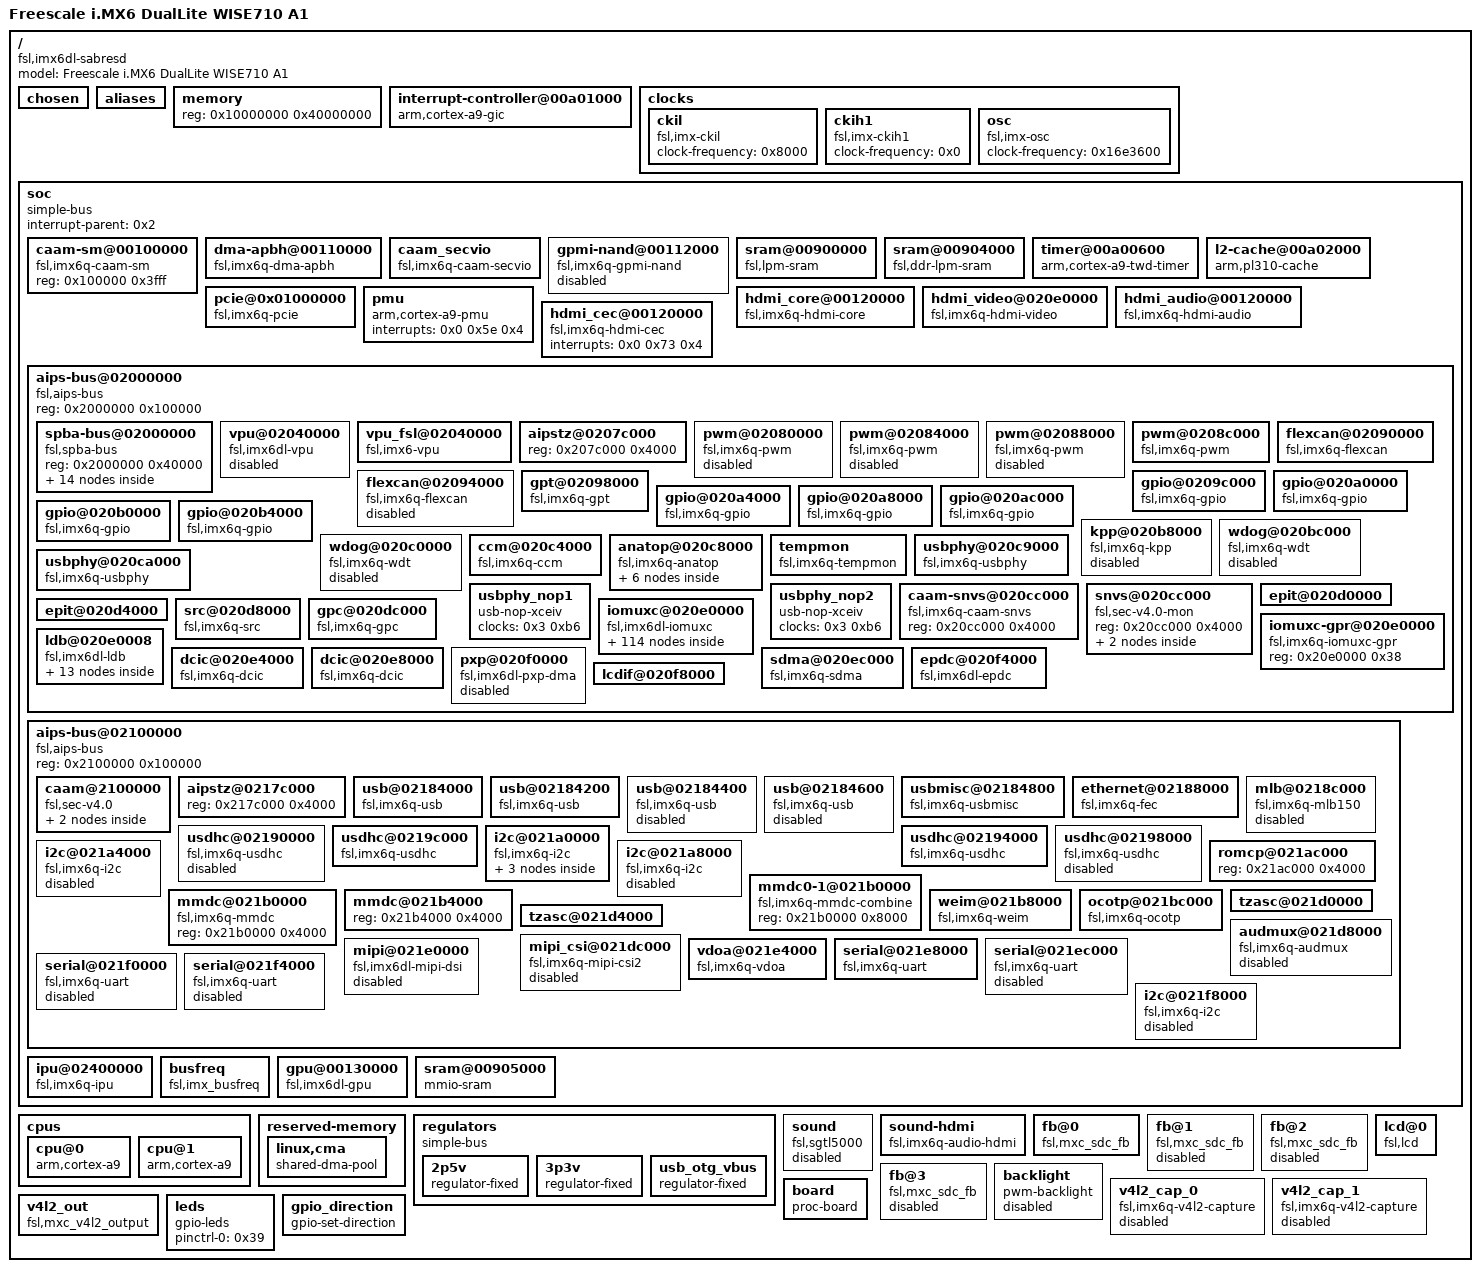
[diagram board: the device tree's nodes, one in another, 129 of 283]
/dts-v1/;

/ {
	#address-cells = <0x1>;
	#size-cells = <0x1>;
	model = "Freescale i.MX6 DualLite WISE710 A1";
	compatible = "fsl,imx6dl-sabresd", "fsl,imx6dl";

	chosen {
	};

	aliases {
		ethernet0 = "/soc/aips-bus@02100000/ethernet@02188000";
		can0 = "/soc/aips-bus@02000000/flexcan@02090000";
		can1 = "/soc/aips-bus@02000000/flexcan@02094000";
		gpio0 = "/soc/aips-bus@02000000/gpio@0209c000";
		gpio1 = "/soc/aips-bus@02000000/gpio@020a0000";
		gpio2 = "/soc/aips-bus@02000000/gpio@020a4000";
		gpio3 = "/soc/aips-bus@02000000/gpio@020a8000";
		gpio4 = "/soc/aips-bus@02000000/gpio@020ac000";
		gpio5 = "/soc/aips-bus@02000000/gpio@020b0000";
		gpio6 = "/soc/aips-bus@02000000/gpio@020b4000";
		i2c0 = "/soc/aips-bus@02100000/i2c@021a0000";
		i2c1 = "/soc/aips-bus@02100000/i2c@021a4000";
		i2c2 = "/soc/aips-bus@02100000/i2c@021a8000";
		ipu0 = "/soc/ipu@02400000";
		mmc0 = "/soc/aips-bus@02100000/usdhc@02190000";
		mmc1 = "/soc/aips-bus@02100000/usdhc@02194000";
		mmc2 = "/soc/aips-bus@02100000/usdhc@02198000";
		mmc3 = "/soc/aips-bus@02100000/usdhc@0219c000";
		serial0 = "/soc/aips-bus@02000000/spba-bus@02000000/serial@02020000";
		serial1 = "/soc/aips-bus@02100000/serial@021e8000";
		serial2 = "/soc/aips-bus@02100000/serial@021ec000";
		serial3 = "/soc/aips-bus@02100000/serial@021f0000";
		serial4 = "/soc/aips-bus@02100000/serial@021f4000";
		spi0 = "/soc/aips-bus@02000000/spba-bus@02000000/ecspi@02008000";
		spi1 = "/soc/aips-bus@02000000/spba-bus@02000000/ecspi@0200c000";
		spi2 = "/soc/aips-bus@02000000/spba-bus@02000000/ecspi@02010000";
		spi3 = "/soc/aips-bus@02000000/spba-bus@02000000/ecspi@02014000";
		usbphy0 = "/soc/aips-bus@02000000/usbphy@020c9000";
		usbphy1 = "/soc/aips-bus@02000000/usbphy@020ca000";
		i2c3 = "/soc/aips-bus@02100000/i2c@021f8000";
		mxcfb0 = "/fb@0";
		mxcfb1 = "/fb@1";
		mxcfb2 = "/fb@2";
		mxcfb3 = "/fb@3";
	};

	memory {
		device_type = "memory";
		reg = <0x10000000 0x40000000>;
	};

	interrupt-controller@00a01000 {
		compatible = "arm,cortex-a9-gic";
		#interrupt-cells = <0x3>;
		interrupt-controller;
		reg = <0xa01000 0x1000 0xa00100 0x100>;
		interrupt-parent = <0x1>;
		linux,phandle = <0x1>;
		phandle = <0x1>;
	};

	clocks {
		#address-cells = <0x1>;
		#size-cells = <0x0>;

		ckil {
			compatible = "fsl,imx-ckil", "fixed-clock";
			#clock-cells = <0x0>;
			clock-frequency = <0x8000>;
		};

		ckih1 {
			compatible = "fsl,imx-ckih1", "fixed-clock";
			#clock-cells = <0x0>;
			clock-frequency = <0x0>;
		};

		osc {
			compatible = "fsl,imx-osc", "fixed-clock";
			#clock-cells = <0x0>;
			clock-frequency = <0x16e3600>;
		};
	};

	soc {
		#address-cells = <0x1>;
		#size-cells = <0x1>;
		compatible = "simple-bus";
		interrupt-parent = <0x2>;
		ranges;

		caam-sm@00100000 {
			compatible = "fsl,imx6q-caam-sm";
			reg = <0x100000 0x3fff>;
		};

		dma-apbh@00110000 {
			compatible = "fsl,imx6q-dma-apbh", "fsl,imx28-dma-apbh";
			reg = <0x110000 0x2000>;
			interrupts = <0x0 0xd 0x4 0x0 0xd 0x4 0x0 0xd 0x4 0x0 0xd 0x4>;
			interrupt-names = "gpmi0", "gpmi1", "gpmi2", "gpmi3";
			#dma-cells = <0x1>;
			dma-channels = <0x4>;
			clocks = <0x3 0x6a>;
			linux,phandle = <0x4>;
			phandle = <0x4>;
		};

		caam_secvio {
			compatible = "fsl,imx6q-caam-secvio";
			interrupts = <0x0 0x14 0x4>;
			secvio_src = <0x8000001d>;
			jtag-tamper = "disabled";
			watchdog-tamper = "enabled";
			internal-boot-tamper = "enabled";
			external-pin-tamper = "disabled";
		};

		gpmi-nand@00112000 {
			compatible = "fsl,imx6q-gpmi-nand";
			#address-cells = <0x1>;
			#size-cells = <0x1>;
			reg = <0x112000 0x2000 0x114000 0x2000>;
			reg-names = "gpmi-nand", "bch";
			interrupts = <0x0 0xf 0x4>;
			interrupt-names = "bch";
			clocks = <0x3 0x98 0x3 0x99 0x3 0x97 0x3 0x96 0x3 0x95>;
			clock-names = "gpmi_io", "gpmi_apb", "gpmi_bch", "gpmi_bch_apb", "per1_bch";
			dmas = <0x4 0x0>;
			dma-names = "rx-tx";
			status = "disabled";
		};

		sram@00900000 {
			compatible = "fsl,lpm-sram";
			reg = <0x900000 0x4000>;
			clocks = <0x3 0x8e>;
		};

		sram@00904000 {
			compatible = "fsl,ddr-lpm-sram";
			reg = <0x904000 0x1000>;
			clocks = <0x3 0x8e>;
		};

		timer@00a00600 {
			compatible = "arm,cortex-a9-twd-timer";
			reg = <0xa00600 0x20>;
			interrupts = <0x1 0xd 0xf01>;
			interrupt-parent = <0x1>;
			clocks = <0x3 0xf>;
		};

		l2-cache@00a02000 {
			compatible = "arm,pl310-cache";
			reg = <0xa02000 0x1000>;
			interrupts = <0x0 0x5c 0x4>;
			cache-unified;
			cache-level = <0x2>;
			arm,tag-latency = <0x4 0x2 0x3>;
			arm,data-latency = <0x4 0x2 0x3>;
			linux,phandle = <0x30>;
			phandle = <0x30>;
		};

		pcie@0x01000000 {
			compatible = "fsl,imx6q-pcie", "snps,dw-pcie";
			reg = <0x1ffc000 0x4000 0x1f00000 0x80000>;
			reg-names = "dbi", "config";
			#address-cells = <0x3>;
			#size-cells = <0x2>;
			device_type = "pci";
			ranges = <0x800 0x0 0x1f00000 0x1f00000 0x0 0x80000 0x81000000 0x0 0x0 0x1f80000 0x0 0x10000 0x82000000 0x0 0x1000000 0x1000000 0x0 0xf00000>;
			num-lanes = <0x1>;
			interrupts = <0x0 0x78 0x4>;
			interrupt-names = "msi";
			#interrupt-cells = <0x1>;
			interrupt-map-mask = <0x0 0x0 0x0 0x7>;
			interrupt-map = <0x0 0x0 0x0 0x1 0x2 0x0 0x7b 0x4 0x0 0x0 0x0 0x2 0x2 0x0 0x7a 0x4 0x0 0x0 0x0 0x3 0x2 0x0 0x79 0x4 0x0 0x0 0x0 0x4 0x2 0x0 0x78 0x4>;
			clocks = <0x3 0x90 0x3 0xce 0x3 0xbd>;
			clock-names = "pcie", "pcie_bus", "pcie_phy";
			status = "okay";
			pinctrl-names = "default";
			pinctrl-0 = <0x5>;
			disable-gpio = <0x6 0x12 0x0>;
		};

		pmu {
			compatible = "arm,cortex-a9-pmu";
			interrupts = <0x0 0x5e 0x4>;
		};

		hdmi_core@00120000 {
			compatible = "fsl,imx6q-hdmi-core";
			reg = <0x120000 0x9000>;
			clocks = <0x3 0x7c 0x3 0x7b 0x3 0x8a>;
			clock-names = "hdmi_isfr", "hdmi_iahb", "mipi_core";
			status = "okay";
			ipu_id = <0x0>;
			disp_id = <0x1>;
		};

		hdmi_video@020e0000 {
			compatible = "fsl,imx6q-hdmi-video";
			reg = <0x20e0000 0x1000>;
			reg-names = "hdmi_gpr";
			interrupts = <0x0 0x73 0x4>;
			clocks = <0x3 0x7c 0x3 0x7b 0x3 0x8a>;
			clock-names = "hdmi_isfr", "hdmi_iahb", "mipi_core";
			status = "okay";
			fsl,phy_reg_vlev = <0x294>;
			fsl,phy_reg_cksymtx = <0x800d>;
		};

		hdmi_audio@00120000 {
			compatible = "fsl,imx6q-hdmi-audio";
			clocks = <0x3 0x7c 0x3 0x7b 0x3 0x8a>;
			clock-names = "hdmi_isfr", "hdmi_iahb", "mipi_core";
			dmas = <0x7 0x2 0x19 0x0>;
			dma-names = "tx";
			status = "okay";
			linux,phandle = <0x35>;
			phandle = <0x35>;
		};

		hdmi_cec@00120000 {
			compatible = "fsl,imx6q-hdmi-cec";
			interrupts = <0x0 0x73 0x4>;
			status = "okay";
		};

		aips-bus@02000000 {
			compatible = "fsl,aips-bus", "simple-bus";
			#address-cells = <0x1>;
			#size-cells = <0x1>;
			reg = <0x2000000 0x100000>;
			ranges;

			spba-bus@02000000 {
				compatible = "fsl,spba-bus", "simple-bus";
				#address-cells = <0x1>;
				#size-cells = <0x1>;
				reg = <0x2000000 0x40000>;
				ranges;

				spdif@02004000 {
					compatible = "fsl,imx35-spdif";
					reg = <0x2004000 0x4000>;
					interrupts = <0x0 0x34 0x4>;
					dmas = <0x7 0xe 0x12 0x0 0x7 0xf 0x12 0x0>;
					dma-names = "rx", "tx";
					clocks = <0x3 0xf9 0x3 0x3 0x3 0xc5 0x3 0x6b 0x3 0x0 0x3 0x76 0x3 0x3e 0x3 0x8b 0x3 0x0 0x3 0x9c>;
					clock-names = "core", "rxtx0", "rxtx1", "rxtx2", "rxtx3", "rxtx4", "rxtx5", "rxtx6", "rxtx7", "dma";
					status = "disabled";
				};

				ecspi@02008000 {
					#address-cells = <0x1>;
					#size-cells = <0x0>;
					compatible = "fsl,imx6q-ecspi", "fsl,imx51-ecspi";
					reg = <0x2008000 0x4000>;
					interrupts = <0x0 0x1f 0x4>;
					clocks = <0x3 0x70 0x3 0x70>;
					clock-names = "ipg", "per";
					dmas = <0x7 0x3 0x7 0x1 0x7 0x4 0x7 0x2>;
					dma-names = "rx", "tx";
					status = "okay";
					fsl,spi-num-chipselects = <0x2>;
					cs-gpios = <0x8 0x1e 0x0 0x9 0x13 0x0>;
					pinctrl-names = "default";
					pinctrl-0 = <0xa 0xb 0xc>;

					m25p80@0 {
						#address-cells = <0x1>;
						#size-cells = <0x1>;
						compatible = "st,m25p32";
						spi-max-frequency = <0x1312d00>;
						reg = <0x0>;
					};

					fm25@1 {
						compatible = "ramtron,fm25v10";
						spi-max-frequency = <0x2625a00>;
						reg = <0x1>;
					};
				};

				ecspi@0200c000 {
					#address-cells = <0x1>;
					#size-cells = <0x0>;
					compatible = "fsl,imx6q-ecspi", "fsl,imx51-ecspi";
					reg = <0x200c000 0x4000>;
					interrupts = <0x0 0x20 0x4>;
					clocks = <0x3 0x71 0x3 0x71>;
					clock-names = "ipg", "per";
					dmas = <0x7 0x5 0x7 0x1 0x7 0x6 0x7 0x2>;
					dma-names = "rx", "tx";
					status = "disabled";
				};

				ecspi@02010000 {
					#address-cells = <0x1>;
					#size-cells = <0x0>;
					compatible = "fsl,imx6q-ecspi", "fsl,imx51-ecspi";
					reg = <0x2010000 0x4000>;
					interrupts = <0x0 0x21 0x4>;
					clocks = <0x3 0x72 0x3 0x72>;
					clock-names = "ipg", "per";
					dmas = <0x7 0x7 0x7 0x1 0x7 0x8 0x7 0x2>;
					dma-names = "rx", "tx";
					status = "disabled";
				};

				ecspi@02014000 {
					#address-cells = <0x1>;
					#size-cells = <0x0>;
					compatible = "fsl,imx6q-ecspi", "fsl,imx51-ecspi";
					reg = <0x2014000 0x4000>;
					interrupts = <0x0 0x22 0x4>;
					clocks = <0x3 0x73 0x3 0x73>;
					clock-names = "ipg", "per";
					dmas = <0x7 0x9 0x7 0x1 0x7 0xa 0x7 0x2>;
					dma-names = "rx", "tx";
					status = "disabled";
				};

				serial@02020000 {
					compatible = "fsl,imx6q-uart", "fsl,imx21-uart";
					reg = <0x2020000 0x4000>;
					interrupts = <0x0 0x1a 0x4>;
					clocks = <0x3 0xa0 0x3 0xa1>;
					clock-names = "ipg", "per";
					dmas = <0x7 0x19 0x4 0x0 0x7 0x1a 0x4 0x0>;
					dma-names = "rx", "tx";
					status = "okay";
					pinctrl-names = "default";
					pinctrl-0 = <0xd>;
				};

				esai@02024000 {
					#sound-dai-cells = <0x0>;
					compatible = "fsl,imx35-esai";
					reg = <0x2024000 0x4000>;
					interrupts = <0x0 0x33 0x4>;
					clocks = <0x3 0xd9 0x3 0xd0 0x3 0x76 0x3 0xd9 0x3 0x9c>;
					clock-names = "core", "mem", "extal", "fsys", "dma";
					dmas = <0x7 0x17 0x15 0x0 0x7 0x18 0x15 0x0>;
					dma-names = "rx", "tx";
					status = "disabled";
				};

				ssi@02028000 {
					#sound-dai-cells = <0x0>;
					compatible = "fsl,imx6q-ssi", "fsl,imx51-ssi";
					reg = <0x2028000 0x4000>;
					interrupts = <0x0 0x2e 0x4>;
					clocks = <0x3 0xb2 0x3 0x9d>;
					clock-names = "ipg", "baud";
					dmas = <0x7 0x25 0x16 0x0 0x7 0x26 0x16 0x0>;
					dma-names = "rx", "tx";
					fsl,fifo-depth = <0xf>;
					status = "okay";
					linux,phandle = <0x34>;
					phandle = <0x34>;
				};

				ssi@0202c000 {
					#sound-dai-cells = <0x0>;
					compatible = "fsl,imx6q-ssi", "fsl,imx51-ssi";
					reg = <0x202c000 0x4000>;
					interrupts = <0x0 0x2f 0x4>;
					clocks = <0x3 0xb3 0x3 0x9e>;
					clock-names = "ipg", "baud";
					dmas = <0x7 0x29 0x16 0x0 0x7 0x2a 0x16 0x0>;
					dma-names = "rx", "tx";
					fsl,fifo-depth = <0xf>;
					status = "disabled";
				};

				ssi@02030000 {
					#sound-dai-cells = <0x0>;
					compatible = "fsl,imx6q-ssi", "fsl,imx51-ssi";
					reg = <0x2030000 0x4000>;
					interrupts = <0x0 0x30 0x4>;
					clocks = <0x3 0xb4 0x3 0x9f>;
					clock-names = "ipg", "baud";
					dmas = <0x7 0x2d 0x16 0x0 0x7 0x2e 0x16 0x0>;
					dma-names = "rx", "tx";
					fsl,fifo-depth = <0xf>;
					status = "disabled";
				};

				asrc@02034000 {
					compatible = "fsl,imx53-asrc";
					reg = <0x2034000 0x4000>;
					interrupts = <0x0 0x32 0x4>;
					clocks = <0x3 0xda 0x3 0xdb 0x3 0x0 0x3 0x0 0x3 0x0 0x3 0x0 0x3 0x0 0x3 0x0 0x3 0x0 0x3 0x0 0x3 0x0 0x3 0x0 0x3 0x0 0x3 0x0 0x3 0x0 0x3 0x6b 0x3 0x0 0x3 0x0 0x3 0x9c>;
					clock-names = "mem", "ipg", "asrck_0", "asrck_1", "asrck_2", "asrck_3", "asrck_4", "asrck_5", "asrck_6", "asrck_7", "asrck_8", "asrck_9", "asrck_a", "asrck_b", "asrck_c", "asrck_d", "asrck_e", "asrck_f", "dma";
					dmas = <0x7 0x11 0x17 0x1 0x7 0x12 0x17 0x1 0x7 0x13 0x17 0x1 0x7 0x14 0x17 0x1 0x7 0x15 0x17 0x1 0x7 0x16 0x17 0x1>;
					dma-names = "rxa", "rxb", "rxc", "txa", "txb", "txc";
					fsl,asrc-rate = <0xbb80>;
					fsl,asrc-width = <0x10>;
					status = "okay";
				};

				spba@0203c000 {
					reg = <0x203c000 0x4000>;
				};
			};

			vpu@02040000 {
				compatible = "fsl,imx6dl-vpu", "cnm,coda960";
				reg = <0x2040000 0x3c000>;
				interrupts = <0x0 0xc 0x4 0x0 0x3 0x4>;
				interrupt-names = "bit", "jpeg";
				clocks = <0x3 0xa8 0x3 0x8c>;
				clock-names = "per", "ahb";
				resets = <0xe 0x1>;
				iram = <0xf>;
				status = "disabled";
			};

			vpu_fsl@02040000 {
				compatible = "fsl,imx6-vpu";
				reg = <0x2040000 0x3c000>;
				reg-names = "vpu_regs";
				interrupts = <0x0 0x3 0x1 0x0 0xc 0x4>;
				interrupt-names = "vpu_jpu_irq", "vpu_ipi_irq";
				clocks = <0x3 0xa8 0x3 0x8c 0x3 0x8e>;
				clock-names = "vpu_clk", "mmdc_ch0_axi", "ocram";
				iramsize = <0x0>;
				iram = <0xf>;
				resets = <0xe 0x1>;
				power-domains = <0x2 0x1>;
			};

			aipstz@0207c000 {
				reg = <0x207c000 0x4000>;
			};

			pwm@02080000 {
				#pwm-cells = <0x2>;
				compatible = "fsl,imx6q-pwm", "fsl,imx27-pwm";
				reg = <0x2080000 0x4000>;
				interrupts = <0x0 0x53 0x4>;
				clocks = <0x3 0x3e 0x3 0x91>;
				clock-names = "ipg", "per";
				status = "disabled";
			};

			pwm@02084000 {
				#pwm-cells = <0x2>;
				compatible = "fsl,imx6q-pwm", "fsl,imx27-pwm";
				reg = <0x2084000 0x4000>;
				interrupts = <0x0 0x54 0x4>;
				clocks = <0x3 0x3e 0x3 0x92>;
				clock-names = "ipg", "per";
				status = "disabled";
			};

			pwm@02088000 {
				#pwm-cells = <0x2>;
				compatible = "fsl,imx6q-pwm", "fsl,imx27-pwm";
				reg = <0x2088000 0x4000>;
				interrupts = <0x0 0x55 0x4>;
				clocks = <0x3 0x3e 0x3 0x93>;
				clock-names = "ipg", "per";
				status = "disabled";
			};

			pwm@0208c000 {
				#pwm-cells = <0x2>;
				compatible = "fsl,imx6q-pwm", "fsl,imx27-pwm";
				reg = <0x208c000 0x4000>;
				interrupts = <0x0 0x56 0x4>;
				clocks = <0x3 0x3e 0x3 0x94>;
				clock-names = "ipg", "per";
				status = "okay";
				pinctrl-names = "default";
				pinctrl-0 = <0x10>;
			};

			flexcan@02090000 {
				compatible = "fsl,imx6q-flexcan";
				reg = <0x2090000 0x4000>;
				interrupts = <0x0 0x6e 0x4>;
				clocks = <0x3 0x6c 0x3 0x6d>;
				clock-names = "ipg", "per";
				stop-mode = <0x11 0x34 0x1c 0x10 0x11>;
				status = "okay";
				pinctrl-names = "default";
				pinctrl-0 = <0x12>;
			};

			flexcan@02094000 {
				compatible = "fsl,imx6q-flexcan";
				reg = <0x2094000 0x4000>;
				interrupts = <0x0 0x6f 0x4>;
				clocks = <0x3 0x6e 0x3 0x6f>;
				clock-names = "ipg", "per";
				stop-mode = <0x11 0x34 0x1d 0x10 0x12>;
				status = "disabled";
			};

			gpt@02098000 {
				compatible = "fsl,imx6q-gpt", "fsl,imx31-gpt";
				reg = <0x2098000 0x4000>;
				interrupts = <0x0 0x37 0x4>;
				clocks = <0x3 0x77 0x3 0x78 0x3 0xd8>;
				clock-names = "ipg", "per", "osc_per";
			};

			gpio@0209c000 {
				compatible = "fsl,imx6q-gpio", "fsl,imx35-gpio";
				reg = <0x209c000 0x4000>;
				interrupts = <0x0 0x42 0x4 0x0 0x43 0x4>;
				gpio-controller;
				#gpio-cells = <0x2>;
				interrupt-controller;
				#interrupt-cells = <0x2>;
				linux,phandle = <0x28>;
				phandle = <0x28>;
			};

			gpio@020a0000 {
				compatible = "fsl,imx6q-gpio", "fsl,imx35-gpio";
				reg = <0x20a0000 0x4000>;
				interrupts = <0x0 0x44 0x4 0x0 0x45 0x4>;
				gpio-controller;
				#gpio-cells = <0x2>;
				interrupt-controller;
				#interrupt-cells = <0x2>;
				linux,phandle = <0x8>;
				phandle = <0x8>;
			};

			gpio@020a4000 {
				compatible = "fsl,imx6q-gpio", "fsl,imx35-gpio";
				reg = <0x20a4000 0x4000>;
				interrupts = <0x0 0x46 0x4 0x0 0x47 0x4>;
				gpio-controller;
				#gpio-cells = <0x2>;
				interrupt-controller;
				#interrupt-cells = <0x2>;
				linux,phandle = <0x9>;
				phandle = <0x9>;
			};

			gpio@020a8000 {
				compatible = "fsl,imx6q-gpio", "fsl,imx35-gpio";
				reg = <0x20a8000 0x4000>;
				interrupts = <0x0 0x48 0x4 0x0 0x49 0x4>;
				gpio-controller;
				#gpio-cells = <0x2>;
				interrupt-controller;
				#interrupt-cells = <0x2>;
				linux,phandle = <0x33>;
				phandle = <0x33>;
			};

			gpio@020ac000 {
				compatible = "fsl,imx6q-gpio", "fsl,imx35-gpio";
				reg = <0x20ac000 0x4000>;
				interrupts = <0x0 0x4a 0x4 0x0 0x4b 0x4>;
				gpio-controller;
				#gpio-cells = <0x2>;
				interrupt-controller;
				#interrupt-cells = <0x2>;
				linux,phandle = <0x6>;
				phandle = <0x6>;
			};

			gpio@020b0000 {
				compatible = "fsl,imx6q-gpio", "fsl,imx35-gpio";
				reg = <0x20b0000 0x4000>;
				interrupts = <0x0 0x4c 0x4 0x0 0x4d 0x4>;
				gpio-controller;
				#gpio-cells = <0x2>;
				interrupt-controller;
				#interrupt-cells = <0x2>;
				linux,phandle = <0x3a>;
				phandle = <0x3a>;
			};

			gpio@020b4000 {
				compatible = "fsl,imx6q-gpio", "fsl,imx35-gpio";
				reg = <0x20b4000 0x4000>;
				interrupts = <0x0 0x4e 0x4 0x0 0x4f 0x4>;
				gpio-controller;
				#gpio-cells = <0x2>;
				interrupt-controller;
				#interrupt-cells = <0x2>;
			};

			kpp@020b8000 {
				compatible = "fsl,imx6q-kpp", "fsl,imx21-kpp";
				reg = <0x20b8000 0x4000>;
				interrupts = <0x0 0x52 0x4>;
				clocks = <0x3 0x3e>;
				status = "disabled";
			};

			wdog@020bc000 {
				compatible = "fsl,imx6q-wdt", "fsl,imx21-wdt";
				reg = <0x20bc000 0x4000>;
				interrupts = <0x0 0x50 0x4>;
				clocks = <0x3 0x0>;
				status = "disabled";
			};

			wdog@020c0000 {
				compatible = "fsl,imx6q-wdt", "fsl,imx21-wdt";
				reg = <0x20c0000 0x4000>;
				interrupts = <0x0 0x51 0x4>;
				clocks = <0x3 0x0>;
				status = "disabled";
			};

			ccm@020c4000 {
				compatible = "fsl,imx6q-ccm";
				reg = <0x20c4000 0x4000>;
				interrupts = <0x0 0x57 0x4 0x0 0x58 0x4>;
				#clock-cells = <0x1>;
				fsl,ldb-di0-parent = <0x3 0x4>;
				fsl,ldb-di1-parent = <0x3 0x4>;
				linux,phandle = <0x3>;
				phandle = <0x3>;
			};

			anatop@020c8000 {
				compatible = "fsl,imx6q-anatop", "syscon", "simple-bus";
				reg = <0x20c8000 0x1000>;
				interrupts = <0x0 0x31 0x4 0x0 0x36 0x4 0x0 0x7f 0x4>;
				linux,phandle = <0x13>;
				phandle = <0x13>;

				regulator-1p1@110 {
					compatible = "fsl,anatop-regulator";
					regulator-name = "vdd1p1";
					regulator-min-microvolt = <0xc3500>;
					regulator-max-microvolt = <0x14fb18>;
					regulator-always-on;
					anatop-reg-offset = <0x110>;
					anatop-vol-bit-shift = <0x8>;
					anatop-vol-bit-width = <0x5>;
					anatop-min-bit-val = <0x4>;
					anatop-min-voltage = <0xc3500>;
					anatop-max-voltage = <0x14fb18>;
					anatop-enable-bit = <0x0>;
				};

				regulator-3p0@120 {
					compatible = "fsl,anatop-regulator";
					regulator-name = "vdd3p0";
					regulator-min-microvolt = <0x280de8>;
					regulator-max-microvolt = <0x33e140>;
					anatop-reg-offset = <0x120>;
					anatop-vol-bit-shift = <0x8>;
					anatop-vol-bit-width = <0x5>;
					anatop-min-bit-val = <0x0>;
					anatop-min-voltage = <0x280de8>;
					anatop-max-voltage = <0x33e140>;
					anatop-enable-bit = <0x0>;
					linux,phandle = <0x15>;
					phandle = <0x15>;
				};

				regulator-2p5@130 {
					compatible = "fsl,anatop-regulator";
					regulator-name = "vdd2p5";
					regulator-min-microvolt = <0x1e8480>;
					regulator-max-microvolt = <0x29f630>;
					regulator-always-on;
					anatop-reg-offset = <0x130>;
					anatop-vol-bit-shift = <0x8>;
					anatop-vol-bit-width = <0x5>;
					anatop-min-bit-val = <0x0>;
					anatop-min-voltage = <0x1e8480>;
					anatop-max-voltage = <0x29f630>;
					anatop-enable-bit = <0x0>;
				};

				regulator-vddcore@140 {
					compatible = "fsl,anatop-regulator";
					regulator-name = "vddarm";
					regulator-min-microvolt = <0xb1008>;
					regulator-max-microvolt = <0x162010>;
					regulator-always-on;
					anatop-reg-offset = <0x140>;
					anatop-vol-bit-shift = <0x0>;
					anatop-vol-bit-width = <0x5>;
					anatop-delay-reg-offset = <0x170>;
					anatop-delay-bit-shift = <0x18>;
					anatop-delay-bit-width = <0x2>;
					anatop-min-bit-val = <0x1>;
					anatop-min-voltage = <0xb1008>;
					anatop-max-voltage = <0x162010>;
					regulator-allow-bypass;
					linux,phandle = <0x31>;
					phandle = <0x31>;
				};

				regulator-vddpu@140 {
					compatible = "fsl,anatop-regulator";
					regulator-name = "vddpu";
					regulator-min-microvolt = <0xb1008>;
					regulator-max-microvolt = <0x162010>;
					regulator-enable-ramp-delay = <0x96>;
					anatop-reg-offset = <0x140>;
					anatop-vol-bit-shift = <0x9>;
					anatop-vol-bit-width = <0x5>;
					anatop-delay-reg-offset = <0x170>;
					anatop-delay-bit-shift = <0x1a>;
					anatop-delay-bit-width = <0x2>;
					anatop-min-bit-val = <0x1>;
					anatop-min-voltage = <0xb1008>;
					anatop-max-voltage = <0x162010>;
					regulator-allow-bypass;
					linux,phandle = <0x17>;
					phandle = <0x17>;
				};

				regulator-vddsoc@140 {
					compatible = "fsl,anatop-regulator";
					regulator-name = "vddsoc";
					regulator-min-microvolt = <0xb1008>;
					regulator-max-microvolt = <0x162010>;
					regulator-always-on;
					anatop-reg-offset = <0x140>;
					anatop-vol-bit-shift = <0x12>;
					anatop-vol-bit-width = <0x5>;
					anatop-delay-reg-offset = <0x170>;
					anatop-delay-bit-shift = <0x1c>;
					anatop-delay-bit-width = <0x2>;
					anatop-min-bit-val = <0x1>;
					anatop-min-voltage = <0xb1008>;
					anatop-max-voltage = <0x162010>;
					regulator-allow-bypass;
					linux,phandle = <0x32>;
					phandle = <0x32>;
				};
			};

			tempmon {
				compatible = "fsl,imx6q-tempmon";
				interrupts = <0x0 0x31 0x4>;
				fsl,tempmon = <0x13>;
				fsl,tempmon-data = <0x14>;
				clocks = <0x3 0xac>;
			};

			usbphy@020c9000 {
				compatible = "fsl,imx6q-usbphy", "fsl,imx23-usbphy";
				reg = <0x20c9000 0x1000>;
				interrupts = <0x0 0x2c 0x4>;
				clocks = <0x3 0xb6>;
				phy-3p0-supply = <0x15>;
				fsl,anatop = <0x13>;
				tx-d-cal = <0x5>;
				linux,phandle = <0x1c>;
				phandle = <0x1c>;
			};

			usbphy@020ca000 {
				compatible = "fsl,imx6q-usbphy", "fsl,imx23-usbphy";
				reg = <0x20ca000 0x1000>;
				interrupts = <0x0 0x2d 0x4>;
				clocks = <0x3 0xb7>;
				phy-3p0-supply = <0x15>;
				fsl,anatop = <0x13>;
				tx-d-cal = <0x5>;
				linux,phandle = <0x21>;
				phandle = <0x21>;
			};

			usbphy_nop1 {
				compatible = "usb-nop-xceiv";
				clocks = <0x3 0xb6>;
				clock-names = "main_clk";
				linux,phandle = <0x23>;
				phandle = <0x23>;
			};

			usbphy_nop2 {
				compatible = "usb-nop-xceiv";
				clocks = <0x3 0xb6>;
				clock-names = "main_clk";
				linux,phandle = <0x24>;
				phandle = <0x24>;
			};

			caam-snvs@020cc000 {
				compatible = "fsl,imx6q-caam-snvs";
				reg = <0x20cc000 0x4000>;
			};

			snvs@020cc000 {
				compatible = "fsl,sec-v4.0-mon", "syscon", "simple-mfd";
				reg = <0x20cc000 0x4000>;
				linux,phandle = <0x16>;
				phandle = <0x16>;

				snvs-rtc-lp {
					compatible = "fsl,sec-v4.0-mon-rtc-lp";
					regmap = <0x16>;
					offset = <0x34>;
					interrupts = <0x0 0x13 0x4 0x0 0x14 0x4>;
				};

				snvs-poweroff {
					compatible = "syscon-poweroff";
					regmap = <0x16>;
					offset = <0x38>;
					mask = <0x61>;
					status = "okay";
				};
			};

			epit@020d0000 {
				reg = <0x20d0000 0x4000>;
				interrupts = <0x0 0x38 0x4>;
			};

			epit@020d4000 {
				reg = <0x20d4000 0x4000>;
				interrupts = <0x0 0x39 0x4>;
			};

			src@020d8000 {
				compatible = "fsl,imx6q-src", "fsl,imx51-src";
				reg = <0x20d8000 0x4000>;
				interrupts = <0x0 0x5b 0x4 0x0 0x60 0x4>;
				#reset-cells = <0x1>;
				linux,phandle = <0xe>;
				phandle = <0xe>;
			};

			gpc@020dc000 {
				compatible = "fsl,imx6q-gpc";
				reg = <0x20dc000 0x4000>;
				interrupt-controller;
				#interrupt-cells = <0x3>;
				interrupts = <0x0 0x59 0x4 0x0 0x5a 0x4>;
				interrupt-parent = <0x1>;
				pu-supply = <0x17>;
				clocks = <0x3 0x7a 0x3 0x4a 0x3 0x79 0x3 0x1a 0x3 0x8f 0x3 0xa8>;
				#power-domain-cells = <0x1>;
				fsl,ldo-bypass = <0x0>;
				fsl,wdog-reset = <0x1>;
				linux,phandle = <0x2>;
				phandle = <0x2>;
			};

			iomuxc-gpr@020e0000 {
				compatible = "fsl,imx6q-iomuxc-gpr", "syscon";
				reg = <0x20e0000 0x38>;
				linux,phandle = <0x11>;
				phandle = <0x11>;
			};

			iomuxc@020e0000 {
				compatible = "fsl,imx6dl-iomuxc";
				reg = <0x20e0000 0x4000>;
				pinctrl-names = "default";
				pinctrl-0 = <0x18 0x19>;

				enet1 {

					enet1grp-1 {
						fsl,pins = <0x1ec 0x5bc 0x810 0x1 0x0 0x1b0b0 0x1e8 0x5b8 0x0 0x1 0x0 0x1b0b0 0x2d8 0x6c0 0x0 0x1 0x0 0x1b030 0x2c4 0x6ac 0x0 0x1 0x0 0x1b030 0x2c8 0x6b0 0x0 0x1 0x0 0x1b030 0x2cc 0x6b4 0x0 0x1 0x0 0x1b030 0x2d0 0x6b8 0x0 0x1 0x0 0x1b030 0x2d4 0x6bc 0x0 0x1 0x0 0x1b030 0x1f0 0x5c0 0x0 0x1 0x0 0xa0b1 0x2c0 0x6a8 0x814 0x1 0x1 0x1b030 0x2ac 0x694 0x818 0x1 0x1 0x1b030 0x2b0 0x698 0x81c 0x1 0x1 0x1b030 0x2b4 0x69c 0x820 0x1 0x1 0x1b030 0x2b8 0x6a0 0x824 0x1 0x1 0x1b030 0x2bc 0x6a4 0x828 0x1 0x1 0x1b030>;
					};

					enet1_rstgrp-1 {
						fsl,pins = <0x1e4 0x5b4 0x0 0x5 0x0 0x80000000>;
					};
				};

				hog {

					hoggrp-1 {
						fsl,pins = <0x224 0x5f4 0x0 0x5 0x0 0x80000000 0x22c 0x5fc 0x0 0x5 0x0 0x80000000 0x17c 0x54c 0x0 0x5 0x0 0x1b0b0 0x180 0x550 0x0 0x5 0x0 0x130b0>;
						linux,phandle = <0x18>;
						phandle = <0x18>;
					};

					hoggrp-2 {
						fsl,pins = <0x98 0x3ac 0x0 0x5 0x0 0x1b0b0 0x74 0x388 0x0 0x5 0x0 0x1b0b0 0x78 0x38c 0x0 0x5 0x0 0x1b0b0 0x27c 0x664 0x0 0x5 0x0 0x1b0b0 0x26c 0x654 0x0 0x5 0x0 0x1b0b0 0x284 0x66c 0x0 0x5 0x0 0x1b0b0 0x294 0x67c 0x0 0x5 0x0 0x17059>;
						linux,phandle = <0x19>;
						phandle = <0x19>;
					};
				};

				lvds {

					lvds_bklgrp-1 {
						fsl,pins = <0x244 0x62c 0x0 0x5 0x0 0x170b0>;
						linux,phandle = <0x37>;
						phandle = <0x37>;
					};

					lvds_vccgrp-1 {
						fsl,pins = <0x258 0x640 0x0 0x5 0x0 0x170b0>;
						linux,phandle = <0x38>;
						phandle = <0x38>;
					};
				};

				audmux {

					audmux-1 {
						fsl,pins = <0x2fc 0x6e4 0x798 0x3 0x1 0x130b0 0x308 0x6f0 0x7a8 0x3 0x1 0x130b0 0x304 0x6ec 0x79c 0x3 0x1 0x110b0 0x300 0x6e8 0x7ac 0x3 0x1 0x130b0>;
					};

					audmux-2 {
						fsl,pins = <0x80 0x394 0x0 0x4 0x0 0x130b0 0x74 0x388 0x0 0x4 0x0 0x130b0 0x78 0x38c 0x0 0x4 0x0 0x110b0 0x7c 0x390 0x0 0x4 0x0 0x130b0>;
					};

					audmux-3 {
						fsl,pins = <0xd0 0x3e4 0x7c0 0x3 0x0 0x130b0 0xd8 0x3ec 0x7c4 0x3 0x0 0x130b0 0xdc 0x3f0 0x7b0 0x3 0x0 0x130b0>;
					};

					audmux-4 {
						fsl,pins = <0xe4 0x3f8 0x7a8 0x3 0x0 0x130b0 0xe8 0x3fc 0x79c 0x3 0x0 0x130b0 0xec 0x400 0x7ac 0x3 0x0 0x130b0 0xf0 0x404 0x798 0x3 0x0 0x130b0>;
						linux,phandle = <0x2e>;
						phandle = <0x2e>;
					};
				};

				ecspi1 {

					ecspi1_cs_grp-1 {
						fsl,pins = <0x150 0x520 0x0 0x5 0x0 0x80000000>;
						linux,phandle = <0xc>;
						phandle = <0xc>;
					};

					ecspi1grp-1 {
						fsl,pins = <0x148 0x518 0x7dc 0x1 0x2 0x100b1 0x14c 0x51c 0x7e0 0x1 0x2 0x100b1 0x144 0x514 0x7d8 0x1 0x2 0x100b1>;
						linux,phandle = <0xa>;
						phandle = <0xa>;
					};

					ecspi1grp-2 {
						fsl,pins = <0x248 0x630 0x7dc 0x0 0x3 0x100b1 0x258 0x640 0x7e0 0x0 0x3 0x100b1 0x244 0x62c 0x7d8 0x0 0x3 0x100b1>;
					};
				};

				ecspi3 {

					ecspi3grp-1 {
						fsl,pins = <0xe0 0x3f4 0x0 0x2 0x0 0x100b1 0xb4 0x3c8 0x0 0x2 0x0 0x100b1 0xb0 0x3c4 0x0 0x2 0x0 0x100b1>;
					};
				};

				enet {

					enetgrp-1 {
						fsl,pins = <0x1ec 0x5bc 0x810 0x1 0x0 0x1b0b0 0x1e8 0x5b8 0x0 0x1 0x0 0x1b0b0 0x2d8 0x6c0 0x0 0x1 0x0 0x1b0b0 0x2c4 0x6ac 0x0 0x1 0x0 0x1b0b0 0x2c8 0x6b0 0x0 0x1 0x0 0x1b0b0 0x2cc 0x6b4 0x0 0x1 0x0 0x1b0b0 0x2d0 0x6b8 0x0 0x1 0x0 0x1b0b0 0x2d4 0x6bc 0x0 0x1 0x0 0x1b0b0 0x1f0 0x5c0 0x0 0x1 0x0 0x1b0b0 0x2c0 0x6a8 0x814 0x1 0x1 0x1b0b0 0x2ac 0x694 0x818 0x1 0x1 0x1b0b0 0x2b0 0x698 0x81c 0x1 0x1 0x1b0b0 0x2b4 0x69c 0x820 0x1 0x1 0x1b0b0 0x2b8 0x6a0 0x824 0x1 0x1 0x1b0b0 0x2bc 0x6a4 0x828 0x1 0x1 0x1b0b0 0x214 0x5e4 0x80c 0x2 0x0 0x4001b0a8>;
						linux,phandle = <0x25>;
						phandle = <0x25>;
					};

					enetgrp-2 {
						fsl,pins = <0x248 0x630 0x810 0x1 0x1 0x1b0b0 0x24c 0x634 0x0 0x4 0x0 0x1b0b0 0x2d8 0x6c0 0x0 0x1 0x0 0x1b0b0 0x2c4 0x6ac 0x0 0x1 0x0 0x1b0b0 0x2c8 0x6b0 0x0 0x1 0x0 0x1b0b0 0x2cc 0x6b4 0x0 0x1 0x0 0x1b0b0 0x2d0 0x6b8 0x0 0x1 0x0 0x1b0b0 0x2d4 0x6bc 0x0 0x1 0x0 0x1b0b0 0x1f0 0x5c0 0x0 0x1 0x0 0x1b0b0 0x2c0 0x6a8 0x814 0x1 0x1 0x1b0b0 0x2ac 0x694 0x818 0x1 0x1 0x1b0b0 0x2b0 0x698 0x81c 0x1 0x1 0x1b0b0 0x2b4 0x69c 0x820 0x1 0x1 0x1b0b0 0x2b8 0x6a0 0x824 0x1 0x1 0x1b0b0 0x2bc 0x6a4 0x828 0x1 0x1 0x1b0b0 0x214 0x5e4 0x80c 0x2 0x0 0x4001b0a8>;
					};

					enetgrp-3 {
						fsl,pins = <0x1ec 0x5bc 0x810 0x1 0x0 0x1b0b0 0x1e8 0x5b8 0x0 0x1 0x0 0x1b0b0 0x2d8 0x6c0 0x0 0x1 0x0 0x1b0b0 0x2c4 0x6ac 0x0 0x1 0x0 0x1b0b0 0x2c8 0x6b0 0x0 0x1 0x0 0x1b0b0 0x2cc 0x6b4 0x0 0x1 0x0 0x1b0b0 0x2d0 0x6b8 0x0 0x1 0x0 0x1b0b0 0x2d4 0x6bc 0x0 0x1 0x0 0x1b0b0 0x1f0 0x5c0 0x0 0x1 0x0 0x1b0b0 0x2c0 0x6a8 0x814 0x1 0x1 0x1b0b0 0x2ac 0x694 0x818 0x1 0x1 0x1b0b0 0x2b0 0x698 0x81c 0x1 0x1 0x1b0b0 0x2b4 0x69c 0x820 0x1 0x1 0x1b0b0 0x2b8 0x6a0 0x824 0x1 0x1 0x1b0b0 0x2bc 0x6a4 0x828 0x1 0x1 0x1b0b0 0x200 0x5d0 0x0 0x1 0x0 0x1b0b0>;
					};

					enetirqgrp {
						fsl,pins = <0x234 0x604 0x3c 0x11 0xff000609 0xb1>;
					};
				};

				esai {

					esaigrp-1 {
						fsl,pins = <0x1f8 0x5c8 0x838 0x2 0x0 0x1b030 0x1e4 0x5b4 0x840 0x2 0x0 0x1b030 0x1fc 0x5cc 0x830 0x2 0x0 0x1b030 0x200 0x5d0 0x850 0x2 0x0 0x1b030 0x208 0x5d8 0x84c 0x2 0x0 0x1b030 0x204 0x5d4 0x854 0x2 0x0 0x1b030 0x1e8 0x5b8 0x858 0x2 0x0 0x1b030 0x27c 0x664 0x844 0x2 0x1 0x1b030 0x280 0x668 0x848 0x2 0x1 0x1b030>;
					};

					esaigrp-2 {
						fsl,pins = <0x1e4 0x5b4 0x840 0x2 0x0 0x1b030 0x1fc 0x5cc 0x830 0x2 0x0 0x1b030 0x200 0x5d0 0x850 0x2 0x0 0x1b030 0x230 0x600 0x84c 0x0 0x1 0x1b030 0x204 0x5d4 0x854 0x2 0x0 0x1b030 0x1e8 0x5b8 0x858 0x2 0x0 0x1b030 0x218 0x5e8 0x844 0x0 0x0 0x1b030 0x280 0x668 0x848 0x2 0x1 0x1b030 0x1ec 0x5bc 0x83c 0x2 0x0 0x1b030 0x240 0x610 0x82c 0x0 0x1 0x1b030>;
					};
				};

				can1 {

					flexcan1grp-1 {
						fsl,pins = <0x260 0x648 0x7c8 0x2 0x1 0x80000000 0x24c 0x634 0x0 0x2 0x0 0x80000000>;
						linux,phandle = <0x12>;
						phandle = <0x12>;
					};

					flexcan1grp-2 {
						fsl,pins = <0x238 0x608 0x0 0x3 0x0 0x80000000 0x260 0x648 0x7c8 0x2 0x1 0x80000000>;
					};

					flexcan1grp-3 {
						fsl,pins = <0x238 0x608 0x0 0x3 0x0 0x80000000 0x23c 0x60c 0x7c8 0x3 0x0 0x80000000>;
					};
				};

				can2 {

					flexcan2grp-1 {
						fsl,pins = <0x254 0x63c 0x0 0x0 0x0 0x80000000 0x268 0x650 0x7cc 0x0 0x0 0x80000000>;
					};
				};

				hdmi_hdcp {

					hdmihdcpgrp-1 {
						fsl,pins = <0x250 0x638 0x860 0x2 0x1 0x4001b8b1 0x264 0x64c 0x864 0x2 0x1 0x4001b8b1>;
					};

					hdmihdcpgrp-2 {
						fsl,pins = <0x1cc 0x59c 0x860 0x4 0x0 0x4001b8b1 0x144 0x514 0x864 0x4 0x0 0x4001b8b1>;
					};

					hdmihdcpgrp-3 {
						fsl,pins = <0x1cc 0x59c 0x860 0x4 0x0 0x4001b8b1 0x264 0x64c 0x864 0x2 0x1 0x4001b8b1>;
					};
				};

				hdmi_cec {

					hdmicecgrp-1 {
						fsl,pins = <0x134 0x504 0x85c 0x6 0x0 0x1f8b0>;
					};

					hdmicecgrp-2 {
						fsl,pins = <0x260 0x648 0x85c 0x6 0x1 0x1f8b0>;
					};
				};

				i2c1 {

					i2c1grp-1 {
						fsl,pins = <0x158 0x528 0x868 0x6 0x1 0x4001b8b1 0x174 0x544 0x86c 0x1 0x1 0x4001b8b1>;
					};

					i2c1grp-2 {
						fsl,pins = <0x84 0x398 0x86c 0x4 0x0 0x4001b8b1 0x88 0x39c 0x868 0x4 0x0 0x4001b8b1>;
						linux,phandle = <0x29>;
						phandle = <0x29>;
					};
				};

				i2c2 {

					i2c2grp-1 {
						fsl,pins = <0x1cc 0x59c 0x870 0x6 0x0 0x4001b8b1 0x144 0x514 0x874 0x6 0x0 0x4001b8b1>;
					};

					i2c2grp-2 {
						fsl,pins = <0x250 0x638 0x870 0x4 0x1 0x4001b8b1 0x264 0x64c 0x874 0x4 0x1 0x4001b8b1>;
						linux,phandle = <0x2c>;
						phandle = <0x2c>;
					};

					i2c2grp-3 {
						fsl,pins = <0x1cc 0x59c 0x870 0x6 0x0 0x4001b8b1 0x264 0x64c 0x874 0x4 0x1 0x4001b8b1>;
					};
				};

				i2c3 {

					i2c3grp-1 {
						fsl,pins = <0x148 0x518 0x878 0x6 0x0 0x4001b8b1 0x14c 0x51c 0x87c 0x6 0x0 0x4001b8b1>;
					};

					i2c3grp-2 {
						fsl,pins = <0x228 0x5f8 0x878 0x2 0x1 0x4001b8b1 0x234 0x604 0x87c 0x2 0x2 0x4001b8b1>;
						linux,phandle = <0x2d>;
						phandle = <0x2d>;
					};

					i2c3grp-3 {
						fsl,pins = <0x230 0x600 0x878 0x6 0x2 0x4001b8b1 0x214 0x5e4 0x87c 0x6 0x1 0x4001b8b1>;
					};

					i2c3grp-4 {
						fsl,pins = <0x228 0x5f8 0x878 0x2 0x1 0x4001b8b1 0x14c 0x51c 0x87c 0x6 0x0 0x4001b8b1>;
					};
				};

				ipu1 {

					ipu1grp-1 {
						fsl,pins = <0x9c 0x3b0 0x0 0x0 0x0 0x10 0xa0 0x3b4 0x0 0x0 0x0 0x10 0xa4 0x3b8 0x0 0x0 0x0 0x10 0xa8 0x3bc 0x0 0x0 0x0 0x10 0xac 0x3c0 0x0 0x0 0x0 0x80000000 0xb0 0x3c4 0x0 0x0 0x0 0x10 0xb4 0x3c8 0x0 0x0 0x0 0x10 0xe0 0x3f4 0x0 0x0 0x0 0x10 0xf4 0x408 0x0 0x0 0x0 0x10 0xf8 0x40c 0x0 0x0 0x0 0x10 0xfc 0x410 0x0 0x0 0x0 0x10 0x100 0x414 0x0 0x0 0x0 0x10 0x104 0x418 0x0 0x0 0x0 0x10 0x108 0x41c 0x0 0x0 0x0 0x10 0x10c 0x420 0x0 0x0 0x0 0x10 0xb8 0x3cc 0x0 0x0 0x0 0x10 0xbc 0x3d0 0x0 0x0 0x0 0x10 0xc0 0x3d4 0x0 0x0 0x0 0x10 0xc4 0x3d8 0x0 0x0 0x0 0x10 0xc8 0x3dc 0x0 0x0 0x0 0x10 0xcc 0x3e0 0x0 0x0 0x0 0x10 0xd0 0x3e4 0x0 0x0 0x0 0x10 0xd4 0x3e8 0x0 0x0 0x0 0x10 0xd8 0x3ec 0x0 0x0 0x0 0x10 0xdc 0x3f0 0x0 0x0 0x0 0x10 0xe4 0x3f8 0x0 0x0 0x0 0x10 0xe8 0x3fc 0x0 0x0 0x0 0x10 0xec 0x400 0x0 0x0 0x0 0x10 0xf0 0x404 0x0 0x0 0x0 0x10>;
						linux,phandle = <0x36>;
						phandle = <0x36>;
					};

					ipu1grp-2 {
						fsl,pins = <0x54 0x368 0x0 0x0 0x0 0x80000000 0x58 0x36c 0x0 0x0 0x0 0x80000000 0x5c 0x370 0x0 0x0 0x0 0x80000000 0x60 0x374 0x0 0x0 0x0 0x80000000 0x64 0x378 0x0 0x0 0x0 0x80000000 0x68 0x37c 0x0 0x0 0x0 0x80000000 0x6c 0x380 0x0 0x0 0x0 0x80000000 0x70 0x384 0x0 0x0 0x0 0x80000000 0x8c 0x3a0 0x0 0x0 0x0 0x80000000 0x94 0x3a8 0x0 0x0 0x0 0x80000000 0x90 0x3a4 0x0 0x0 0x0 0x80000000 0x98 0x3ac 0x0 0x0 0x0 0x80000000>;
					};

					ipu1grp-3 {
						fsl,pins = <0x74 0x388 0x0 0x0 0x0 0x80000000 0x78 0x38c 0x0 0x0 0x0 0x80000000 0x7c 0x390 0x0 0x0 0x0 0x80000000 0x80 0x394 0x0 0x0 0x0 0x80000000 0x84 0x398 0x0 0x0 0x0 0x80000000 0x88 0x39c 0x0 0x0 0x0 0x80000000 0x4c 0x360 0x0 0x0 0x0 0x80000000 0x50 0x364 0x0 0x0 0x0 0x80000000 0x54 0x368 0x0 0x0 0x0 0x80000000 0x58 0x36c 0x0 0x0 0x0 0x80000000 0x5c 0x370 0x0 0x0 0x0 0x80000000 0x60 0x374 0x0 0x0 0x0 0x80000000 0x64 0x378 0x0 0x0 0x0 0x80000000 0x68 0x37c 0x0 0x0 0x0 0x80000000 0x6c 0x380 0x0 0x0 0x0 0x80000000 0x70 0x384 0x0 0x0 0x0 0x80000000 0x94 0x3a8 0x0 0x0 0x0 0x80000000 0x90 0x3a4 0x0 0x0 0x0 0x80000000 0x98 0x3ac 0x0 0x0 0x0 0x80000000>;
					};
				};

				pwm1 {

					pwm1grp-1 {
						fsl,pins = <0x2f0 0x6d8 0x0 0x3 0x0 0x1b0b1>;
					};
				};

				pwm3 {

					pwm3grp-1 {
						fsl,pins = <0x344 0x72c 0x0 0x2 0x0 0x1b0b1>;
					};
				};

				spdif {

					spdifgrp-1 {
						fsl,pins = <0x250 0x638 0x8f0 0x6 0x3 0x1b0b0>;
					};

					spdifgrp-2 {
						fsl,pins = <0x214 0x5e4 0x8f0 0x4 0x2 0x1b0b0 0x218 0x5e8 0x0 0x4 0x0 0x1b0b0>;
					};
				};

				uart1 {

					uart1grp-1 {
						fsl,pins = <0x4c 0x360 0x0 0x3 0x0 0x1b0b1 0x50 0x364 0x8fc 0x3 0x1 0x1b0b1>;
						linux,phandle = <0xd>;
						phandle = <0xd>;
					};
				};

				uart2 {

					uart2grp-1 {
						fsl,pins = <0x16c 0x53c 0x0 0x4 0x0 0x1b0b1 0x170 0x540 0x904 0x4 0x1 0x1b0b1>;
					};

					uart2grp-2 {
						fsl,pins = <0x16c 0x53c 0x904 0x4 0x0 0x1b0b1 0x170 0x540 0x0 0x4 0x0 0x1b0b1 0x174 0x544 0x900 0x4 0x0 0x1b0b1 0x178 0x548 0x0 0x4 0x0 0x1b0b1>;
					};

					uart2grp-3 {
						fsl,pins = <0x16c 0x53c 0x0 0x4 0x0 0x1b0b1 0x170 0x540 0x904 0x4 0x1 0x1b0b1>;
						linux,phandle = <0x2f>;
						phandle = <0x2f>;
					};
				};

				uart3 {

					uart3grp-1 {
						fsl,pins = <0x338 0x720 0x90c 0x2 0x2 0x1b0b1 0x33c 0x724 0x0 0x2 0x0 0x1b0b1 0x17c 0x54c 0x0 0x4 0x0 0x1b0b1 0x1d0 0x5a0 0x908 0x2 0x3 0x1b0b1>;
					};

					uart3dtegrp-1 {
						fsl,pins = <0x338 0x720 0x0 0x2 0x0 0x1b0b1 0x33c 0x724 0x90c 0x2 0x3 0x1b0b1 0x17c 0x54c 0x908 0x4 0x1 0x1b0b1 0x1d0 0x5a0 0x0 0x2 0x0 0x1b0b1>;
					};
				};

				uart4 {

					uart4grp-1 {
						fsl,pins = <0x244 0x62c 0x0 0x4 0x0 0x1b0b1 0x258 0x640 0x914 0x4 0x3 0x1b0b1>;
					};
				};

				uart5 {

					uart5grp-1 {
						fsl,pins = <0x248 0x630 0x0 0x4 0x0 0x1b0b1 0x25c 0x644 0x91c 0x4 0x3 0x1b0b1 0x254 0x63c 0x918 0x4 0x2 0x1b0b1 0x268 0x650 0x0 0x4 0x0 0x1b0b1>;
					};

					uart5dtegrp-1 {
						fsl,pins = <0x25c 0x644 0x0 0x4 0x0 0x1b0b1 0x248 0x630 0x91c 0x4 0x2 0x1b0b1 0x268 0x650 0x918 0x4 0x3 0x1b0b1 0x254 0x63c 0x0 0x4 0x0 0x1b0b1>;
					};
				};

				usbotg {

					usbotggrp-1 {
						fsl,pins = <0x210 0x5e0 0x790 0x3 0x1 0x17059>;
						linux,phandle = <0x1e>;
						phandle = <0x1e>;
					};

					usbotggrp-2 {
						fsl,pins = <0x1f4 0x5c4 0x790 0x0 0x0 0x17059>;
					};

					usbotg_pwr_grp-1 {
						fsl,pins = <0x268 0x650 0x0 0x5 0x0 0x80000000 0x254 0x63c 0x0 0x5 0x0 0x1b0b0>;
						linux,phandle = <0x1f>;
						phandle = <0x1f>;
					};
				};

				usbh2 {

					usbh2grp-1 {
						fsl,pins = <0x2d8 0x6c0 0x0 0x0 0x0 0x40013030 0x2d4 0x6bc 0x0 0x0 0x0 0x40013030>;
					};

					usbh2grp-2 {
						fsl,pins = <0x2d4 0x6bc 0x0 0x0 0x0 0x40017030>;
					};
				};

				usbh3 {

					usbh3grp-1 {
						fsl,pins = <0x2bc 0x6a4 0x0 0x0 0x0 0x40013030 0x2c0 0x6a8 0x0 0x0 0x0 0x40013030>;
					};

					usbh3grp-2 {
						fsl,pins = <0x2c0 0x6a8 0x0 0x0 0x0 0x40017030>;
					};
				};

				usdhc1 {

					usdhc1grp-1 {
						fsl,pins = <0x2e0 0x6c8 0x0 0x0 0x0 0x17059 0x2dc 0x6c4 0x928 0x0 0x1 0x10059 0x2e4 0x6cc 0x0 0x0 0x0 0x17059 0x2e8 0x6d0 0x0 0x0 0x0 0x17059 0x2ec 0x6d4 0x0 0x0 0x0 0x17059 0x2f0 0x6d8 0x0 0x0 0x0 0x17059>;
					};
				};

				usdhc2 {

					usdhc2grp-1 {
						fsl,pins = <0x2f8 0x6e0 0x0 0x0 0x0 0x17059 0x2f4 0x6dc 0x930 0x0 0x1 0x10059 0x2fc 0x6e4 0x0 0x0 0x0 0x17059 0x300 0x6e8 0x0 0x0 0x0 0x17059 0x304 0x6ec 0x0 0x0 0x0 0x17059 0x308 0x6f0 0x0 0x0 0x0 0x17059 0x294 0x67c 0x0 0x1 0x0 0x17059 0x298 0x680 0x0 0x1 0x0 0x17059 0x29c 0x684 0x0 0x1 0x0 0x17059 0x2a0 0x688 0x0 0x1 0x0 0x17059>;
					};

					usdhc2grp-2 {
						fsl,pins = <0x2f8 0x6e0 0x0 0x0 0x0 0x17059 0x2f4 0x6dc 0x930 0x0 0x1 0x10059 0x2fc 0x6e4 0x0 0x0 0x0 0x17059 0x300 0x6e8 0x0 0x0 0x0 0x17059 0x304 0x6ec 0x0 0x0 0x0 0x17059 0x308 0x6f0 0x0 0x0 0x0 0x17059>;
						linux,phandle = <0x27>;
						phandle = <0x27>;
					};
				};

				usdhc3 {

					usdhc3grp-1 {
						fsl,pins = <0x310 0x6f8 0x0 0x0 0x0 0x17059 0x30c 0x6f4 0x934 0x0 0x1 0x10059 0x314 0x6fc 0x0 0x0 0x0 0x17059 0x318 0x700 0x0 0x0 0x0 0x17059 0x31c 0x704 0x0 0x0 0x0 0x17059 0x320 0x708 0x0 0x0 0x0 0x17059 0x324 0x70c 0x0 0x0 0x0 0x17059 0x328 0x710 0x0 0x0 0x0 0x17059 0x32c 0x714 0x0 0x0 0x0 0x17059 0x330 0x718 0x0 0x0 0x0 0x17059>;
					};

					usdhc3grp-1-100mhz {
						fsl,pins = <0x310 0x6f8 0x0 0x0 0x0 0x170b9 0x30c 0x6f4 0x934 0x0 0x1 0x100b9 0x314 0x6fc 0x0 0x0 0x0 0x170b9 0x318 0x700 0x0 0x0 0x0 0x170b9 0x31c 0x704 0x0 0x0 0x0 0x170b9 0x320 0x708 0x0 0x0 0x0 0x170b9 0x324 0x70c 0x0 0x0 0x0 0x170b9 0x328 0x710 0x0 0x0 0x0 0x170b9 0x32c 0x714 0x0 0x0 0x0 0x170b9 0x330 0x718 0x0 0x0 0x0 0x170b9>;
					};

					usdhc3grp-1-200mhz {
						fsl,pins = <0x310 0x6f8 0x0 0x0 0x0 0x170f9 0x30c 0x6f4 0x934 0x0 0x1 0x100f9 0x314 0x6fc 0x0 0x0 0x0 0x170f9 0x318 0x700 0x0 0x0 0x0 0x170f9 0x31c 0x704 0x0 0x0 0x0 0x170f9 0x320 0x708 0x0 0x0 0x0 0x170f9 0x324 0x70c 0x0 0x0 0x0 0x170f9 0x328 0x710 0x0 0x0 0x0 0x170f9 0x32c 0x714 0x0 0x0 0x0 0x170f9 0x330 0x718 0x0 0x0 0x0 0x170f9>;
					};

					usdhc3grp-2 {
						fsl,pins = <0x310 0x6f8 0x0 0x0 0x0 0x17059 0x30c 0x6f4 0x934 0x0 0x1 0x10059 0x314 0x6fc 0x0 0x0 0x0 0x17059 0x318 0x700 0x0 0x0 0x0 0x17059 0x31c 0x704 0x0 0x0 0x0 0x17059 0x320 0x708 0x0 0x0 0x0 0x17059>;
					};
				};

				usdhc4 {

					usdhc4grp-1 {
						fsl,pins = <0x33c 0x724 0x0 0x0 0x0 0x17059 0x338 0x720 0x938 0x0 0x1 0x10059 0x340 0x728 0x0 0x1 0x0 0x17059 0x344 0x72c 0x0 0x1 0x0 0x17059 0x348 0x730 0x0 0x1 0x0 0x17059 0x34c 0x734 0x0 0x1 0x0 0x17059 0x350 0x738 0x0 0x1 0x0 0x17059 0x354 0x73c 0x0 0x1 0x0 0x17059 0x358 0x740 0x0 0x1 0x0 0x17059 0x35c 0x744 0x0 0x1 0x0 0x17059>;
						linux,phandle = <0x26>;
						phandle = <0x26>;
					};

					usdhc4grp-2 {
						fsl,pins = <0x33c 0x724 0x0 0x0 0x0 0x17059 0x338 0x720 0x938 0x0 0x1 0x10059 0x340 0x728 0x0 0x1 0x0 0x17059 0x344 0x72c 0x0 0x1 0x0 0x17059 0x348 0x730 0x0 0x1 0x0 0x17059 0x34c 0x734 0x0 0x1 0x0 0x17059>;
					};
				};

				leds {

					leds_debug1grp-1 {
						fsl,pins = <0x230 0x600 0x0 0x5 0x0 0x80000000 0x234 0x604 0x0 0x5 0x0 0x80000000 0x218 0x5e8 0x0 0x5 0x0 0x130b0 0x1f8 0x5c8 0x0 0x5 0x0 0x80000000 0x208 0x5d8 0x0 0x5 0x0 0x80000000 0x1e4 0x5b4 0x0 0x5 0x0 0x80000000 0x204 0x5d4 0x0 0x5 0x0 0x80000000 0x220 0x5f0 0x0 0x5 0x0 0x80000000 0x238 0x608 0x0 0x5 0x0 0x80000000 0x23c 0x60c 0x0 0x5 0x0 0x80000000 0x21c 0x5ec 0x0 0x5 0x0 0x80000000 0x244 0x62c 0x0 0x5 0x0 0x130b0 0x258 0x640 0x0 0x5 0x0 0x130b0>;
						linux,phandle = <0x39>;
						phandle = <0x39>;
					};
				};

				pcie {

					pcie1grp-1 {
						fsl,pins = <0x94 0x3a8 0x0 0x5 0x0 0x80000000>;
						linux,phandle = <0x5>;
						phandle = <0x5>;
					};
				};

				pwm4 {

					pwm4grp-1 {
						fsl,pins = <0x2e0 0x6c8 0x0 0x2 0x0 0x1b0b1>;
						linux,phandle = <0x10>;
						phandle = <0x10>;
					};
				};

				spi1 {

					ecspi1_cs_grp-0 {
						fsl,pins = <0x1cc 0x59c 0x0 0x5 0x0 0x80000000>;
						linux,phandle = <0xb>;
						phandle = <0xb>;
					};
				};

				usbh1 {

					usbh1_grp-1 {
						fsl,pins = <0x20c 0x5dc 0x0 0x5 0x0 0x17099 0x228 0x5f8 0x0 0x5 0x0 0x1b8b1>;
						linux,phandle = <0x22>;
						phandle = <0x22>;
					};
				};

				wdt {

					wdt_engrp-1 {
						fsl,pins = <0x298 0x680 0x0 0x5 0x0 0x80000000>;
						linux,phandle = <0x2a>;
						phandle = <0x2a>;
					};

					wdt_pinggrp-1 {
						fsl,pins = <0x240 0x610 0x0 0x5 0x0 0x80000000>;
						linux,phandle = <0x2b>;
						phandle = <0x2b>;
					};
				};
			};

			ldb@020e0008 {
				#address-cells = <0x1>;
				#size-cells = <0x0>;
				gpr = <0x11>;
				status = "okay";
				compatible = "fsl,imx6dl-ldb", "fsl,imx53-ldb";
				clocks = <0x3 0x87 0x3 0x88 0x3 0x27 0x3 0x28 0x3 0x29 0x3 0xb8 0x3 0xb9 0x3 0xd1 0x3 0xd2 0x3 0xd3 0x3 0xd4>;
				clock-names = "ldb_di0", "ldb_di1", "di0_sel", "di1_sel", "di2_sel", "ldb_di0_div_3_5", "ldb_di1_div_3_5", "ldb_di0_div_7", "ldb_di1_div_7", "ldb_di0_div_sel", "ldb_di1_div_sel";

				lvds-channel@0 {
					#address-cells = <0x1>;
					#size-cells = <0x0>;
					reg = <0x0>;
					status = "okay";
					fsl,data-mapping = "spwg";
					fsl,data-width = <0x18>;
					crtc = "ipu1-di0";
					primary;

					display-timings {
						native-mode = <0x1a>;

						g070vw01v0 {
							clock-frequency = <0x1c22260>;
							hactive = <0x320>;
							vactive = <0x1e0>;
							hback-porch = <0x60>;
							hfront-porch = <0x18>;
							vback-porch = <0x3>;
							vfront-porch = <0xa>;
							hsync-len = <0x48>;
							vsync-len = <0x7>;
						};

						g150xgel04 {
							clock-frequency = <0x3c8eee0>;
							hactive = <0x400>;
							vactive = <0x300>;
							hback-porch = <0x98>;
							hfront-porch = <0x30>;
							vback-porch = <0x3>;
							vfront-porch = <0x17>;
							hsync-len = <0x68>;
							vsync-len = <0x4>;
						};

						g190eg01v1 {
							clock-frequency = <0x67f3540>;
							hactive = <0x500>;
							vactive = <0x400>;
							hback-porch = <0xd8>;
							hfront-porch = <0x50>;
							vback-porch = <0x3>;
							vfront-porch = <0x1d>;
							hsync-len = <0x88>;
							vsync-len = <0x7>;
						};

						g215hvn0 {
							clock-frequency = <0xa21fe80>;
							hactive = <0x780>;
							vactive = <0x438>;
							hback-porch = <0x5a>;
							hfront-porch = <0x1e>;
							vback-porch = <0x5>;
							vfront-porch = <0x26>;
							hsync-len = <0x3c>;
							vsync-len = <0x7>;
						};

						g150xgel05 {
							clock-frequency = <0x3dfd240>;
							hactive = <0x400>;
							vactive = <0x300>;
							hback-porch = <0xdc>;
							hfront-porch = <0x28>;
							vback-porch = <0x15>;
							vfront-porch = <0x7>;
							hsync-len = <0x3c>;
							vsync-len = <0xa>;
						};

						g070y2l01 {
							clock-frequency = <0x1c22260>;
							hactive = <0x320>;
							vactive = <0x1e0>;
							hback-porch = <0x60>;
							hfront-porch = <0x18>;
							vback-porch = <0x3>;
							vfront-porch = <0xa>;
							hsync-len = <0x48>;
							vsync-len = <0x7>;
							linux,phandle = <0x1a>;
							phandle = <0x1a>;
						};
					};
				};

				lvds-channel@1 {
					#address-cells = <0x1>;
					#size-cells = <0x0>;
					reg = <0x1>;
					status = "disabled";
					fsl,data-mapping = "spwg";
					fsl,data-width = <0x18>;
					crtc = "ipu1-di1";

					display-timings {
						native-mode = <0x1b>;

						g070vw01v0 {
							clock-frequency = <0x1c22260>;
							hactive = <0x320>;
							vactive = <0x1e0>;
							hback-porch = <0x60>;
							hfront-porch = <0x18>;
							vback-porch = <0x3>;
							vfront-porch = <0xa>;
							hsync-len = <0x48>;
							vsync-len = <0x7>;
							linux,phandle = <0x1b>;
							phandle = <0x1b>;
						};

						g150xgel04 {
							clock-frequency = <0x3c8eee0>;
							hactive = <0x400>;
							vactive = <0x300>;
							hback-porch = <0x98>;
							hfront-porch = <0x30>;
							vback-porch = <0x3>;
							vfront-porch = <0x17>;
							hsync-len = <0x68>;
							vsync-len = <0x4>;
						};

						g150xgel05 {
							clock-frequency = <0x3dfd240>;
							hactive = <0x400>;
							vactive = <0x300>;
							hback-porch = <0xdc>;
							hfront-porch = <0x28>;
							vback-porch = <0x15>;
							vfront-porch = <0x7>;
							hsync-len = <0x3c>;
							vsync-len = <0xa>;
						};
					};
				};
			};

			dcic@020e4000 {
				compatible = "fsl,imx6q-dcic";
				reg = <0x20e4000 0x4000>;
				interrupts = <0x0 0x7c 0x4>;
				clocks = <0x3 0xd6 0x3 0xd6>;
				clock-names = "dcic", "disp-axi";
				gpr = <0x11>;
				status = "okay";
				dcic_id = <0x0>;
				dcic_mux = "dcic-hdmi";
			};

			dcic@020e8000 {
				compatible = "fsl,imx6q-dcic";
				reg = <0x20e8000 0x4000>;
				interrupts = <0x0 0x7d 0x4>;
				clocks = <0x3 0xd6 0x3 0xd7>;
				clock-names = "dcic", "disp-axi";
				gpr = <0x11>;
				status = "okay";
				dcic_id = <0x1>;
				dcic_mux = "dcic-lcdif1";
			};

			sdma@020ec000 {
				compatible = "fsl,imx6q-sdma", "fsl,imx35-sdma";
				reg = <0x20ec000 0x4000>;
				interrupts = <0x0 0x2 0x4>;
				clocks = <0x3 0x9b 0x3 0x9b>;
				clock-names = "ipg", "ahb";
				#dma-cells = <0x3>;
				fsl,sdma-ram-script-name = "imx/sdma/sdma-imx6q.bin";
				linux,phandle = <0x7>;
				phandle = <0x7>;
			};

			pxp@020f0000 {
				compatible = "fsl,imx6dl-pxp-dma";
				reg = <0x20f0000 0x4000>;
				interrupts = <0x0 0x62 0x4>;
				clocks = <0x3 0x85 0x3 0x0>;
				clock-names = "pxp-axi", "disp-axi";
				status = "disabled";
			};

			epdc@020f4000 {
				compatible = "fsl,imx6dl-epdc";
				reg = <0x20f4000 0x4000>;
				interrupts = <0x0 0x61 0x4>;
				clocks = <0x3 0x85 0x3 0x89>;
				clock-names = "epdc_axi", "epdc_pix";
			};

			lcdif@020f8000 {
				reg = <0x20f8000 0x4000>;
				interrupts = <0x0 0x27 0x4>;
			};
		};

		aips-bus@02100000 {
			compatible = "fsl,aips-bus", "simple-bus";
			#address-cells = <0x1>;
			#size-cells = <0x1>;
			reg = <0x2100000 0x100000>;
			ranges;

			caam@2100000 {
				compatible = "fsl,sec-v4.0";
				#address-cells = <0x1>;
				#size-cells = <0x1>;
				reg = <0x2100000 0x40000>;
				ranges = <0x0 0x2100000 0x40000>;
				interrupt-parent = <0x1>;
				clocks = <0x3 0xf6 0x3 0xf7 0x3 0xf8 0x3 0xc4>;
				clock-names = "caam_mem", "caam_aclk", "caam_ipg", "caam_emi_slow";

				jr0@1000 {
					compatible = "fsl,sec-v4.0-job-ring";
					reg = <0x1000 0x1000>;
					interrupt-parent = <0x1>;
					interrupts = <0x0 0x69 0x4>;
				};

				jr1@2000 {
					compatible = "fsl,sec-v4.0-job-ring";
					reg = <0x2000 0x1000>;
					interrupt-parent = <0x1>;
					interrupts = <0x0 0x6a 0x4>;
				};
			};

			aipstz@0217c000 {
				reg = <0x217c000 0x4000>;
			};

			usb@02184000 {
				compatible = "fsl,imx6q-usb", "fsl,imx27-usb";
				reg = <0x2184000 0x200>;
				interrupts = <0x0 0x2b 0x4>;
				clocks = <0x3 0xa2>;
				fsl,usbphy = <0x1c>;
				fsl,usbmisc = <0x1d 0x0>;
				ahb-burst-config = <0x0>;
				tx-burst-size-dword = <0x10>;
				rx-burst-size-dword = <0x10>;
				fsl,anatop = <0x13>;
				status = "okay";
				pinctrl-names = "default";
				pinctrl-0 = <0x1e 0x1f>;
				vbus-supply = <0x20>;
				imx6-usb-charger-detection;
			};

			usb@02184200 {
				compatible = "fsl,imx6q-usb", "fsl,imx27-usb";
				reg = <0x2184200 0x200>;
				interrupts = <0x0 0x28 0x4>;
				clocks = <0x3 0xa2>;
				fsl,usbphy = <0x21>;
				fsl,usbmisc = <0x1d 0x1>;
				dr_mode = "host";
				ahb-burst-config = <0x0>;
				tx-burst-size-dword = <0x10>;
				rx-burst-size-dword = <0x10>;
				status = "okay";
				pinctrl-names = "default";
				pinctrl-0 = <0x22>;
			};

			usb@02184400 {
				compatible = "fsl,imx6q-usb", "fsl,imx27-usb";
				reg = <0x2184400 0x200>;
				interrupts = <0x0 0x29 0x4>;
				clocks = <0x3 0xa2>;
				fsl,usbmisc = <0x1d 0x2>;
				dr_mode = "host";
				ahb-burst-config = <0x0>;
				tx-burst-size-dword = <0x10>;
				rx-burst-size-dword = <0x10>;
				phy_type = "hsic";
				fsl,usbphy = <0x23>;
				fsl,anatop = <0x13>;
				status = "disabled";
			};

			usb@02184600 {
				compatible = "fsl,imx6q-usb", "fsl,imx27-usb";
				reg = <0x2184600 0x200>;
				interrupts = <0x0 0x2a 0x4>;
				clocks = <0x3 0xa2>;
				fsl,usbmisc = <0x1d 0x3>;
				dr_mode = "host";
				ahb-burst-config = <0x0>;
				tx-burst-size-dword = <0x10>;
				rx-burst-size-dword = <0x10>;
				phy_type = "hsic";
				fsl,usbphy = <0x24>;
				fsl,anatop = <0x13>;
				status = "disabled";
			};

			usbmisc@02184800 {
				#index-cells = <0x1>;
				compatible = "fsl,imx6q-usbmisc";
				reg = <0x2184800 0x200>;
				clocks = <0x3 0xa2>;
				linux,phandle = <0x1d>;
				phandle = <0x1d>;
			};

			ethernet@02188000 {
				compatible = "fsl,imx6q-fec";
				reg = <0x2188000 0x4000>;
				interrupts-extended = <0x2 0x0 0x76 0x4 0x2 0x0 0x77 0x4>;
				clocks = <0x3 0x75 0x3 0x75 0x3 0xbe>;
				clock-names = "ipg", "ahb", "ptp";
				stop-mode = <0x11 0x34 0x1b>;
				fsl,wakeup_irq = <0x0>;
				status = "okay";
				pinctrl-names = "default";
				pinctrl-0 = <0x25>;
				phy-mode = "rgmii";
				fsl,magic-packet;
			};

			mlb@0218c000 {
				compatible = "fsl,imx6q-mlb150";
				reg = <0x218c000 0x4000>;
				interrupts = <0x0 0x35 0x4 0x0 0x75 0x4 0x0 0x7e 0x4>;
				clocks = <0x3 0x8b 0x3 0xaf>;
				clock-names = "mlb", "pll8_mlb";
				iram = <0xf>;
				status = "disabled";
			};

			usdhc@02190000 {
				compatible = "fsl,imx6q-usdhc";
				reg = <0x2190000 0x4000>;
				interrupts = <0x0 0x16 0x4>;
				clocks = <0x3 0xa3 0x3 0xa3 0x3 0xa3>;
				clock-names = "ipg", "ahb", "per";
				bus-width = <0x4>;
				status = "disabled";
			};

			usdhc@0219c000 {
				compatible = "fsl,imx6q-usdhc";
				reg = <0x219c000 0x4000>;
				interrupts = <0x0 0x19 0x4>;
				clocks = <0x3 0xa6 0x3 0xa6 0x3 0xa6>;
				clock-names = "ipg", "ahb", "per";
				bus-width = <0x8>;
				status = "okay";
				pinctrl-names = "default";
				pinctrl-0 = <0x26>;
				non-removable;
				no-1-8-v;
				keep-power-in-suspend;
			};

			usdhc@02194000 {
				compatible = "fsl,imx6q-usdhc";
				reg = <0x2194000 0x4000>;
				interrupts = <0x0 0x17 0x4>;
				clocks = <0x3 0xa4 0x3 0xa4 0x3 0xa4>;
				clock-names = "ipg", "ahb", "per";
				bus-width = <0x4>;
				status = "okay";
				pinctrl-names = "default";
				pinctrl-0 = <0x27>;
				cd-gpios = <0x28 0x4 0x0>;
				wp-gpios = <0x28 0x2 0x0>;
				no-1-8-v;
				keep-power-in-suspend;
				enable-sdio-wakeup;
			};

			usdhc@02198000 {
				compatible = "fsl,imx6q-usdhc";
				reg = <0x2198000 0x4000>;
				interrupts = <0x0 0x18 0x4>;
				clocks = <0x3 0xa5 0x3 0xa5 0x3 0xa5>;
				clock-names = "ipg", "ahb", "per";
				bus-width = <0x4>;
				status = "disabled";
			};

			i2c@021a0000 {
				#address-cells = <0x1>;
				#size-cells = <0x0>;
				compatible = "fsl,imx6q-i2c", "fsl,imx21-i2c";
				reg = <0x21a0000 0x4000>;
				interrupts = <0x0 0x24 0x4>;
				clocks = <0x3 0x7d>;
				status = "okay";
				clock-frequency = <0x186a0>;
				pinctrl-names = "default";
				pinctrl-0 = <0x29>;

				wdt@29 {
					compatible = "fsl,adv-wdt-i2c";
					pinctrl-names = "default";
					pinctrl-0 = <0x2a 0x2b>;
					status = "okay";
					wdt-en = <0x8 0x5 0x0>;
					wdt-ping = <0x28 0x9 0x0>;
					reg = <0x29>;
				};

				rx8010@32 {
					compatible = "epson,rx8010";
					reg = <0x32>;
				};

				ecc508a@60 {
					compatible = "atmel,ecc508a";
					reg = <0x60>;
				};
			};

			i2c@021a4000 {
				#address-cells = <0x1>;
				#size-cells = <0x0>;
				compatible = "fsl,imx6q-i2c", "fsl,imx21-i2c";
				reg = <0x21a4000 0x4000>;
				interrupts = <0x0 0x25 0x4>;
				clocks = <0x3 0x7e>;
				status = "disabled";
				clock-frequency = <0x186a0>;
				pinctrl-names = "default";
				pinctrl-0 = <0x2c>;
			};

			i2c@021a8000 {
				#address-cells = <0x1>;
				#size-cells = <0x0>;
				compatible = "fsl,imx6q-i2c", "fsl,imx21-i2c";
				reg = <0x21a8000 0x4000>;
				interrupts = <0x0 0x26 0x4>;
				clocks = <0x3 0x7f>;
				status = "disabled";
				clock-frequency = <0x186a0>;
				pinctrl-names = "default";
				pinctrl-0 = <0x2d>;
			};

			romcp@021ac000 {
				reg = <0x21ac000 0x4000>;
			};

			mmdc0-1@021b0000 {
				compatible = "fsl,imx6q-mmdc-combine";
				reg = <0x21b0000 0x8000>;
			};

			mmdc@021b0000 {
				compatible = "fsl,imx6q-mmdc";
				reg = <0x21b0000 0x4000>;
			};

			mmdc@021b4000 {
				reg = <0x21b4000 0x4000>;
			};

			weim@021b8000 {
				compatible = "fsl,imx6q-weim";
				reg = <0x21b8000 0x4000>;
				interrupts = <0x0 0xe 0x4>;
				clocks = <0x3 0xc4>;
			};

			ocotp@021bc000 {
				compatible = "fsl,imx6q-ocotp", "syscon";
				reg = <0x21bc000 0x4000>;
				clocks = <0x3 0x80>;
				linux,phandle = <0x14>;
				phandle = <0x14>;
			};

			tzasc@021d0000 {
				reg = <0x21d0000 0x4000>;
				interrupts = <0x0 0x6c 0x4>;
			};

			tzasc@021d4000 {
				reg = <0x21d4000 0x4000>;
				interrupts = <0x0 0x6d 0x4>;
			};

			audmux@021d8000 {
				compatible = "fsl,imx6q-audmux", "fsl,imx31-audmux";
				reg = <0x21d8000 0x4000>;
				status = "disabled";
				pinctrl-names = "default";
				pinctrl-0 = <0x2e>;
			};

			mipi_csi@021dc000 {
				compatible = "fsl,imx6q-mipi-csi2";
				reg = <0x21dc000 0x4000>;
				interrupts = <0x0 0x64 0x4 0x0 0x65 0x4>;
				clocks = <0x3 0x8a 0x3 0x35 0x3 0xd5>;
				clock-names = "dphy_clk", "pixel_clk", "cfg_clk";
				status = "disabled";
				ipu_id = <0x0>;
				csi_id = <0x1>;
				v_channel = <0x0>;
				lanes = <0x2>;
			};

			mipi@021e0000 {
				reg = <0x21e0000 0x4000>;
				compatible = "fsl,imx6dl-mipi-dsi";
				interrupts = <0x0 0x66 0x4>;
				gpr = <0x11>;
				clocks = <0x3 0x8a 0x3 0xd5>;
				clock-names = "mipi_pllref_clk", "mipi_cfg_clk";
				status = "disabled";
			};

			vdoa@021e4000 {
				compatible = "fsl,imx6q-vdoa";
				reg = <0x21e4000 0x4000>;
				interrupts = <0x0 0x12 0x4>;
				clocks = <0x3 0xca>;
				iram = <0xf>;
			};

			serial@021e8000 {
				compatible = "fsl,imx6q-uart", "fsl,imx21-uart";
				reg = <0x21e8000 0x4000>;
				interrupts = <0x0 0x1b 0x4>;
				clocks = <0x3 0xa0 0x3 0xa1>;
				clock-names = "ipg", "per";
				dmas = <0x7 0x1b 0x4 0x0 0x7 0x1c 0x4 0x0>;
				dma-names = "rx", "tx";
				status = "okay";
				pinctrl-names = "default";
				pinctrl-0 = <0x2f>;
				fsl,uart-has-rtscts;
			};

			serial@021ec000 {
				compatible = "fsl,imx6q-uart", "fsl,imx21-uart";
				reg = <0x21ec000 0x4000>;
				interrupts = <0x0 0x1c 0x4>;
				clocks = <0x3 0xa0 0x3 0xa1>;
				clock-names = "ipg", "per";
				dmas = <0x7 0x1d 0x4 0x0 0x7 0x1e 0x4 0x0>;
				dma-names = "rx", "tx";
				status = "disabled";
			};

			serial@021f0000 {
				compatible = "fsl,imx6q-uart", "fsl,imx21-uart";
				reg = <0x21f0000 0x4000>;
				interrupts = <0x0 0x1d 0x4>;
				clocks = <0x3 0xa0 0x3 0xa1>;
				clock-names = "ipg", "per";
				dmas = <0x7 0x1f 0x4 0x0 0x7 0x20 0x4 0x0>;
				dma-names = "rx", "tx";
				status = "disabled";
			};

			serial@021f4000 {
				compatible = "fsl,imx6q-uart", "fsl,imx21-uart";
				reg = <0x21f4000 0x4000>;
				interrupts = <0x0 0x1e 0x4>;
				clocks = <0x3 0xa0 0x3 0xa1>;
				clock-names = "ipg", "per";
				dmas = <0x7 0x21 0x4 0x0 0x7 0x22 0x4 0x0>;
				dma-names = "rx", "tx";
				status = "disabled";
			};

			i2c@021f8000 {
				#address-cells = <0x1>;
				#size-cells = <0x0>;
				compatible = "fsl,imx6q-i2c", "fsl,imx21-i2c";
				reg = <0x21f8000 0x4000>;
				interrupts = <0x0 0x23 0x4>;
				clocks = <0x3 0x74>;
				status = "disabled";
			};
		};

		ipu@02400000 {
			#address-cells = <0x1>;
			#size-cells = <0x0>;
			compatible = "fsl,imx6q-ipu";
			reg = <0x2400000 0x400000>;
			interrupts = <0x0 0x6 0x4 0x0 0x5 0x4>;
			clocks = <0x3 0x82 0x3 0x83 0x3 0x84 0x3 0x27 0x3 0x28 0x3 0x87 0x3 0x88>;
			clock-names = "bus", "di0", "di1", "di0_sel", "di1_sel", "ldb_di0", "ldb_di1";
			resets = <0xe 0x2>;
			bypass_reset = <0x1>;
			status = "okay";
		};

		busfreq {
			compatible = "fsl,imx_busfreq";
			clocks = <0x3 0xab 0x3 0x6 0x3 0xb 0x3 0x68 0x3 0xac 0x3 0x3a 0x3 0x12 0x3 0x3c 0x3 0x14 0x3 0x3 0x3 0xf5 0x3 0x16 0x3 0x8>;
			clock-names = "pll2_bus", "pll2_pfd2_396m", "pll2_198m", "arm", "pll3_usb_otg", "periph", "periph_pre", "periph_clk2", "periph_clk2_sel", "osc", "axi_alt_sel", "axi_sel", "pll3_pfd1_540m";
			interrupts = <0x0 0x6b 0x4 0x0 0x70 0x4>;
			interrupt-names = "irq_busfreq_0", "irq_busfreq_1";
			fsl,max_ddr_freq = <0x17d78400>;
		};

		gpu@00130000 {
			compatible = "fsl,imx6dl-gpu", "fsl,imx6q-gpu";
			reg = <0x130000 0x4000 0x134000 0x4000 0x0 0x0 0x0 0x8000000>;
			reg-names = "iobase_3d", "iobase_2d", "phys_baseaddr", "contiguous_mem";
			interrupts = <0x0 0x9 0x4 0x0 0xa 0x4>;
			interrupt-names = "irq_3d", "irq_2d";
			clocks = <0x3 0x8f 0x3 0x1b 0x3 0x79 0x3 0x7a 0x3 0x0>;
			clock-names = "gpu2d_axi_clk", "gpu3d_axi_clk", "gpu2d_clk", "gpu3d_clk", "gpu3d_shader_clk";
			resets = <0xe 0x0 0xe 0x3>;
			reset-names = "gpu3d", "gpu2d";
			power-domains = <0x2 0x1>;
		};

		sram@00905000 {
			compatible = "mmio-sram";
			reg = <0x905000 0x1b000>;
			clocks = <0x3 0x8e>;
			linux,phandle = <0xf>;
			phandle = <0xf>;
		};
	};

	cpus {
		#address-cells = <0x1>;
		#size-cells = <0x0>;

		cpu@0 {
			compatible = "arm,cortex-a9";
			device_type = "cpu";
			reg = <0x0>;
			next-level-cache = <0x30>;
			operating-points = <0xf32a0 0x1312d0 0xc15c0 0x11edd8 0x60ae0 0x118c30>;
			fsl,soc-operating-points = <0xf32a0 0x11edd8 0xc15c0 0x11edd8 0x60ae0 0x11edd8>;
			clock-latency = <0xee6c>;
			clocks = <0x3 0x68 0x3 0x6 0x3 0x10 0x3 0x11 0x3 0xaa 0x3 0xe7 0x3 0xee 0x3 0xe0>;
			clock-names = "arm", "pll2_pfd2_396m", "step", "pll1_sw", "pll1_sys", "pll1", "pll1_bypass", "pll1_bypass_src";
			arm-supply = <0x31>;
			pu-supply = <0x17>;
			soc-supply = <0x32>;
		};

		cpu@1 {
			compatible = "arm,cortex-a9";
			device_type = "cpu";
			reg = <0x1>;
			next-level-cache = <0x30>;
		};
	};

	reserved-memory {
		#address-cells = <0x1>;
		#size-cells = <0x1>;
		ranges;

		linux,cma {
			compatible = "shared-dma-pool";
			reusable;
			size = <0x14000000>;
			linux,cma-default;
		};
	};

	regulators {
		compatible = "simple-bus";
		#address-cells = <0x1>;
		#size-cells = <0x0>;

		2p5v {
			compatible = "regulator-fixed";
			regulator-name = "2P5V";
			regulator-min-microvolt = <0x2625a0>;
			regulator-max-microvolt = <0x2625a0>;
			regulator-always-on;
		};

		3p3v {
			compatible = "regulator-fixed";
			regulator-name = "3P3V";
			regulator-min-microvolt = <0x325aa0>;
			regulator-max-microvolt = <0x325aa0>;
			regulator-always-on;
		};

		usb_otg_vbus {
			compatible = "regulator-fixed";
			regulator-name = "usb_otg_vbus";
			regulator-min-microvolt = <0x4c4b40>;
			regulator-max-microvolt = <0x4c4b40>;
			gpio = <0x33 0xf 0x0>;
			enable-active-high;
			linux,phandle = <0x20>;
			phandle = <0x20>;
		};
	};

	sound {
		compatible = "fsl,sgtl5000", "fsl,imx-audio-sgtl5000";
		model = "sgtl5000";
		audio-routing = "MIC_IN", "Mic Jack", "Mic Jack", "Mic Bias", "Headphone Jack", "HP_OUT";
		ssi-controller = <0x34>;
		mux-int-port = <0x1>;
		mux-ext-port = <0x4>;
		status = "disabled";
	};

	sound-hdmi {
		compatible = "fsl,imx6q-audio-hdmi", "fsl,imx-audio-hdmi";
		model = "imx-audio-hdmi";
		hdmi-controller = <0x35>;
	};

	fb@0 {
		compatible = "fsl,mxc_sdc_fb";
		disp_dev = "ldb";
		interface_pix_fmt = "RGB24";
		mode_str = "1920x1080M@60";
		default_bpp = <0x20>;
		int_clk = <0x0>;
		late_init = <0x1>;
		status = "okay";
		fb_base = <0x27800000>;
		fb_size = <0x1800000>;
	};

	fb@1 {
		compatible = "fsl,mxc_sdc_fb";
		disp_dev = "lcd";
		interface_pix_fmt = "RGB24";
		mode_str = "1920x1080M@60";
		default_bpp = <0x10>;
		int_clk = <0x0>;
		late_init = <0x0>;
		status = "disabled";
	};

	fb@2 {
		compatible = "fsl,mxc_sdc_fb";
		disp_dev = "ldb";
		interface_pix_fmt = "RGB24";
		default_bpp = <0x10>;
		int_clk = <0x0>;
		late_init = <0x0>;
		status = "disabled";
	};

	fb@3 {
		compatible = "fsl,mxc_sdc_fb";
		disp_dev = "ldb";
		interface_pix_fmt = "RGB24";
		default_bpp = <0x10>;
		int_clk = <0x0>;
		late_init = <0x0>;
		status = "disabled";
	};

	lcd@0 {
		compatible = "fsl,lcd";
		ipu_id = <0x0>;
		disp_id = <0x0>;
		default_ifmt = "RGB565";
		pinctrl-names = "default";
		pinctrl-0 = <0x36>;
		status = "okay";
	};

	backlight {
		pinctrl-names = "default";
		pinctrl-0 = <0x37 0x38>;
		compatible = "pwm-backlight";
		brightness-levels = <0x0 0x4 0x8 0x10 0x20 0x40 0x80 0xff>;
		default-brightness-level = <0x7>;
		status = "disable";
	};

	v4l2_cap_0 {
		compatible = "fsl,imx6q-v4l2-capture";
		ipu_id = <0x0>;
		csi_id = <0x0>;
		mclk_source = <0x0>;
		status = "disabled";
	};

	v4l2_cap_1 {
		compatible = "fsl,imx6q-v4l2-capture";
		ipu_id = <0x0>;
		csi_id = <0x1>;
		mclk_source = <0x0>;
		status = "disabled";
	};

	v4l2_out {
		compatible = "fsl,mxc_v4l2_output";
		status = "okay";
	};

	board {
		compatible = "proc-board";
		board-type = "WISE-710-A2";
		board-cpu = "DualLiteSolo";
	};

	leds {
		compatible = "gpio-leds";
		pinctrl-names = "default";
		pinctrl-0 = <0x39>;
	};

	gpio_direction {
		pinctrl-names = "default";
		compatible = "gpio-set-direction";
		usb-host-pwr-en = <0x28 0x0 0x1>;
		usb-host-oc = <0x28 0x3 0x0>;
		wifi-det = <0x6 0x15 0x0>;
		det-3g = <0x6 0x16 0x0>;
		off-3g = <0x6 0x17 0x0>;
		pcie-h-wlan-led = <0x3a 0xf 0x0>;
		pcie-h-wwan-led = <0x3a 0x8 0x0>;
		pcie-f-wlan-led = <0x8 0x0 0x0>;
		pcie-f-wwan-led = <0x8 0x4 0x0>;
	};
};
